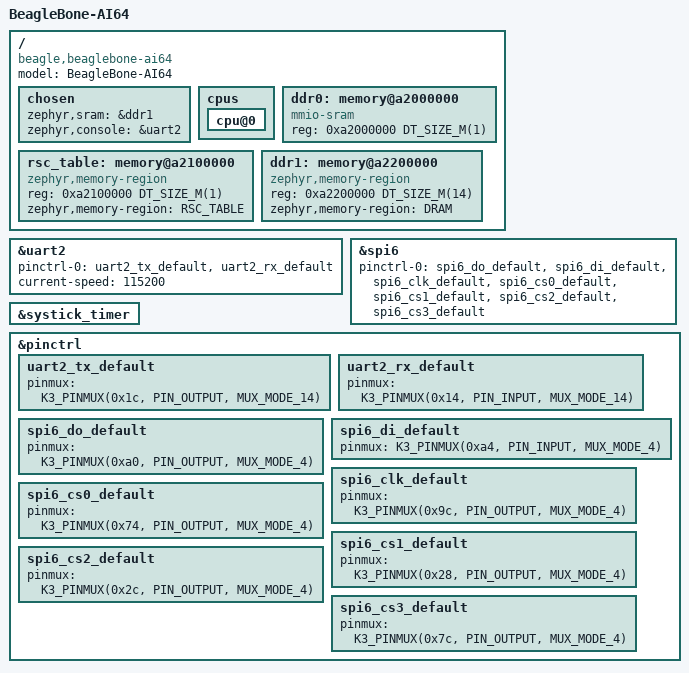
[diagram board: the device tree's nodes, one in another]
/* Copyright (C) 2023 BeagleBoard.org Foundation
 * Copyright (C) 2023 S Prashanth
 * Copyright (c) 2024 Texas Instruments Incorporated
 *	Andrew Davis <afd@ti.com>
 *
 * SPDX-License-Identifier: Apache-2.0
 */

/dts-v1/;

#include <ti/j721e_main_r5.dtsi>
#include <zephyr/dt-bindings/pinctrl/ti-k3-pinctrl.h>
#include <freq.h>

/ {
	model = "BeagleBone-AI64";
	compatible = "beagle,beaglebone-ai64";

	chosen {
		zephyr,sram = &ddr1;
		zephyr,console = &uart2;
	};

	cpus {
		cpu@0 {
			status = "okay";
		};
	};

	ddr0: memory@a2000000 {
		compatible = "mmio-sram";
		reg = <0xa2000000 DT_SIZE_M(1)>;
	};

	rsc_table: memory@a2100000 {
		compatible = "zephyr,memory-region", "mmio-sram";
		reg = <0xa2100000 DT_SIZE_M(1)>;
		zephyr,memory-region = "RSC_TABLE";
	};

	ddr1: memory@a2200000 {
		compatible = "zephyr,memory-region", "mmio-sram";
		reg = <0xa2200000 DT_SIZE_M(14)>;
		zephyr,memory-region = "DRAM";
	};
};

&uart2 {
	status = "okay";
	pinctrl-0 = <&uart2_tx_default &uart2_rx_default>;
	pinctrl-names = "default";
	current-speed = <115200>;
};

&spi6 {
	status = "okay";
	pinctrl-0 = <&spi6_do_default &spi6_di_default &spi6_clk_default
		     &spi6_cs0_default &spi6_cs1_default &spi6_cs2_default
		     &spi6_cs3_default>;
	pinctrl-names = "default";

};

&systick_timer {
	status = "okay";
};

&pinctrl {
	uart2_tx_default: uart2_tx_default {
		/* 0x1c is address of padconfig register of p8.34 and 14 is mux mode */
		pinmux = <K3_PINMUX(0x1c, PIN_OUTPUT, MUX_MODE_14)>;
	};

	uart2_rx_default: uart2_rx_default {
		/* 0x14 is address of padconfig register of p8.22 and 14 is mux mode */
		pinmux = <K3_PINMUX(0x14, PIN_INPUT, MUX_MODE_14)>;
	};

	/* Enable SPI6 */
	spi6_do_default: spi6_do_default {
		/* 0xa0 is the address of padconfig register of P9.21 and 4 is mux mode */
		pinmux = <K3_PINMUX(0xa0, PIN_OUTPUT, MUX_MODE_4)>;
	};

	spi6_di_default: spi6_di_default {
		/* 0xa4 is the address of padconfig register of P9.18 and 4 is mux mode */
		pinmux = <K3_PINMUX(0xa4, PIN_INPUT, MUX_MODE_4)>;
	};

	spi6_clk_default: spi6_clk_default {
		/* 0x9c is the address of padconfig register of P9.22 and 4 is mux mode */
		pinmux = <K3_PINMUX(0x9c, PIN_OUTPUT, MUX_MODE_4)>;
	};

	spi6_cs0_default: spi6_cs0_default {
		/* 0x74 is the address of padconfig register of P9.17 and 4 is mux mode */
		pinmux = <K3_PINMUX(0x74, PIN_OUTPUT, MUX_MODE_4)>;
	};

	spi6_cs1_default: spi6_cs1_default {
		/* 0x28 is the address of padconfig register of P9.23 and 4 is mux mode */
		pinmux = <K3_PINMUX(0x28, PIN_OUTPUT, MUX_MODE_4)>;
	};

	spi6_cs2_default: spi6_cs2_default {
		/* 0x2c is the address of padconfig register of P9.37 and 4 is mux mode */
		pinmux = <K3_PINMUX(0x2c, PIN_OUTPUT, MUX_MODE_4)>;
	};

	spi6_cs3_default: spi6_cs3_default {
		/* 0x7c is the address of padconfig register of P9.21 and 4 is mux mode */
		pinmux = <K3_PINMUX(0x7c, PIN_OUTPUT, MUX_MODE_4)>;
	};


};
